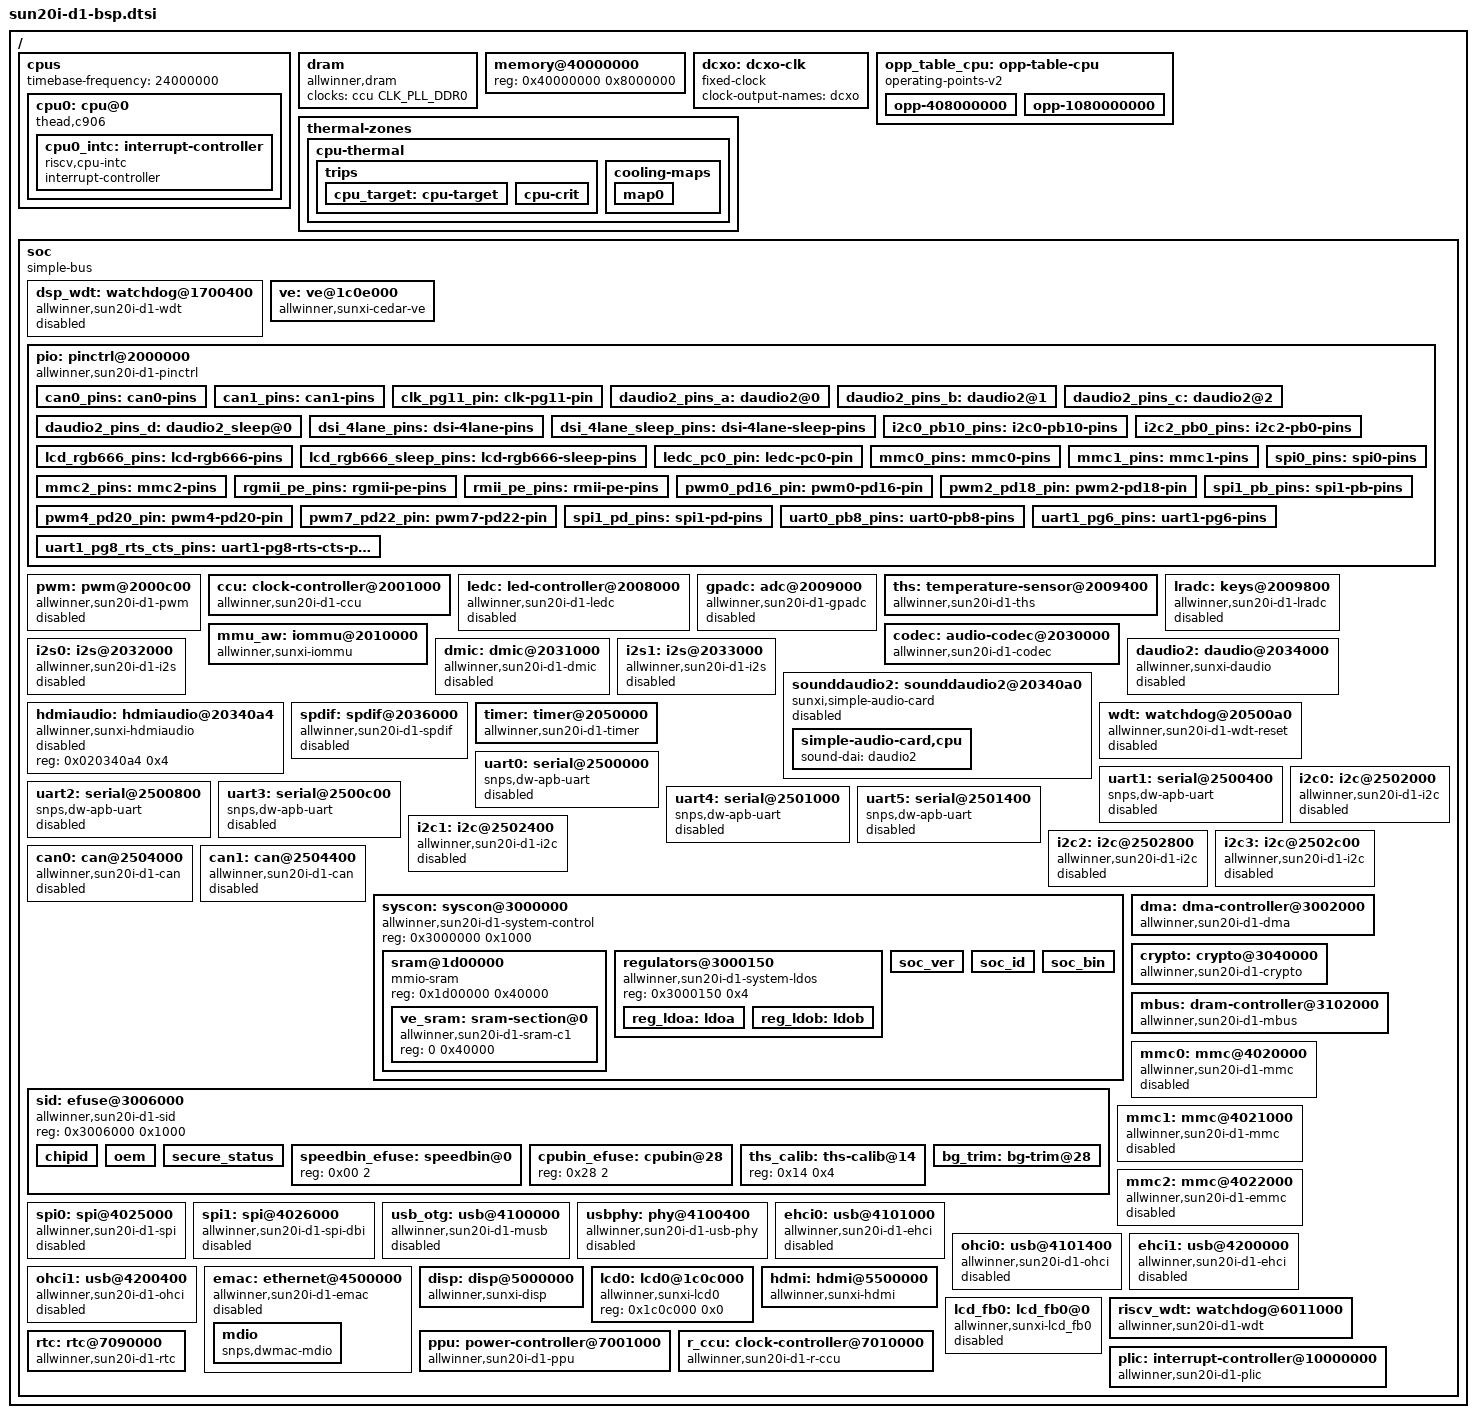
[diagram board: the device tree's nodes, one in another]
// SPDX-License-Identifier: (GPL-2.0+ or MIT)
// Copyright (C) 2021-2022 Samuel Holland <samuel@sholland.org>

/memreserve/ 0x41fc0000 0x020000;  /* opensbi */

#include <dt-bindings/clock/sun6i-rtc.h>
#include <dt-bindings/clock/sun8i-de2.h>
#include <dt-bindings/clock/sun8i-tcon-top.h>
#include <dt-bindings/clock/sun20i-d1-ccu.h>
#include <dt-bindings/clock/sun20i-d1-r-ccu.h>
#include <dt-bindings/gpio/sun4i-gpio.h>
#include <dt-bindings/interrupt-controller/irq.h>
#include <dt-bindings/reset/sun8i-de2.h>
#include <dt-bindings/reset/sun20i-d1-ccu.h>
#include <dt-bindings/reset/sun20i-d1-r-ccu.h>
#include <dt-bindings/thermal/thermal.h>

#define SOC_PERIPHERAL_IRQ(nr)	(nr + 16)

/ {
	#address-cells = <1>;
	#size-cells = <1>;

	cpus {
		timebase-frequency = <24000000>;
		#address-cells = <1>;
		#size-cells = <0>;

		cpu0: cpu@0 {
			compatible = "thead,c906", "riscv";
			device_type = "cpu";
			reg = <0>;
			clocks = <&ccu CLK_RISCV>;
			clock-frequency = <24000000>;
			d-cache-block-size = <64>;
			d-cache-sets = <256>;
			d-cache-size = <32768>;
			i-cache-block-size = <64>;
			i-cache-sets = <128>;
			i-cache-size = <32768>;
			mmu-type = "riscv,sv39";
			operating-points-v2 = <&opp_table_cpu>;
			riscv,isa = "rv64imafdc";
			#cooling-cells = <2>;

			cpu0_intc: interrupt-controller {
				compatible = "riscv,cpu-intc";
				interrupt-controller;
				#address-cells = <0>;
				#interrupt-cells = <1>;
			};
		};
	};

	dram: dram {
		device_type = "dram";
		compatible = "allwinner,dram";
		clocks = <&ccu CLK_PLL_DDR0>;
		clock-names = "pll_ddr";
	};

	memory@40000000 {
		device_type = "memory";
		reg = <0x40000000 0x8000000>;
	};

	dcxo: dcxo-clk {
		compatible = "fixed-clock";
		clock-output-names = "dcxo";
		#clock-cells = <0>;
	};

	opp_table_cpu: opp-table-cpu {
		compatible = "operating-points-v2";

		opp-408000000 {
			opp-hz = /bits/ 64 <408000000>;
			opp-microvolt = <900000 900000 1100000>;
		};

		opp-1080000000 {
			opp-hz = /bits/ 64 <1008000000>;
			opp-microvolt = <900000 900000 1100000>;
		};
	};

	thermal-zones {
		cpu-thermal {
			polling-delay = <0>;
			polling-delay-passive = <0>;
			thermal-sensors = <&ths>;

			trips {
				cpu_target: cpu-target {
					hysteresis = <3000>;
					temperature = <85000>;
					type = "passive";
				};

				cpu-crit {
					hysteresis = <0>;
					temperature = <110000>;
					type = "critical";
				};
			};

			cooling-maps {
				map0 {
					trip = <&cpu_target>;
					cooling-device = <&cpu0 THERMAL_NO_LIMIT THERMAL_NO_LIMIT>;
				};
			};
		};
	};

	soc {
		compatible = "simple-bus";
		ranges;
		interrupt-parent = <&plic>;
		dma-noncoherent;
		#address-cells = <1>;
		#size-cells = <1>;

		dsp_wdt: watchdog@1700400 {
			compatible = "allwinner,sun20i-d1-wdt";
			reg = <0x1700400 0x20>;
			interrupts = <SOC_PERIPHERAL_IRQ(122) IRQ_TYPE_LEVEL_HIGH>;
			clocks = <&dcxo>, <&rtc CLK_OSC32K>;
			clock-names = "hosc", "losc";
			status = "reserved";
		};

		ve: ve@1c0e000 {
			compatible = "allwinner,sunxi-cedar-ve";
			reg = <0x01c0e000 0x1000>,
			      <0x03000000 0x10>,
			      <0x03001000 0x1000>;
			//interrupts-extended = <&plic0 82 IRQ_TYPE_LEVEL_HIGH>;
			interrupts = <SOC_PERIPHERAL_IRQ(66) IRQ_TYPE_LEVEL_HIGH>;
			clocks = <&ccu CLK_BUS_VE>, <&ccu CLK_VE>, <&ccu CLK_MBUS_VE>;
			clock-names = "bus_ve", "ve", "mbus_ve";
			resets = <&ccu RST_BUS_VE>;
			iommus = <&mmu_aw 0 1>;
			//iommus = <&iommu 0>;
			status = "okay";
		};

		pio: pinctrl@2000000 {
			compatible = "allwinner,sun20i-d1-pinctrl";
			reg = <0x2000000 0x800>;
			interrupts = <SOC_PERIPHERAL_IRQ(69) IRQ_TYPE_LEVEL_HIGH>,
				     <SOC_PERIPHERAL_IRQ(71) IRQ_TYPE_LEVEL_HIGH>,
				     <SOC_PERIPHERAL_IRQ(73) IRQ_TYPE_LEVEL_HIGH>,
				     <SOC_PERIPHERAL_IRQ(75) IRQ_TYPE_LEVEL_HIGH>,
				     <SOC_PERIPHERAL_IRQ(77) IRQ_TYPE_LEVEL_HIGH>,
				     <SOC_PERIPHERAL_IRQ(79) IRQ_TYPE_LEVEL_HIGH>;
			clocks = <&ccu CLK_APB0>,
				 <&dcxo>,
				 <&rtc CLK_OSC32K>;
			clock-names = "apb", "hosc", "losc";
			gpio-controller;
			interrupt-controller;
			#gpio-cells = <3>;
			#interrupt-cells = <3>;

			/omit-if-no-ref/
			can0_pins: can0-pins {
				pins = "PB2", "PB3";
				function = "can0";
			};

			/omit-if-no-ref/
			can1_pins: can1-pins {
				pins = "PB4", "PB5";
				function = "can1";
			};

			/omit-if-no-ref/
			clk_pg11_pin: clk-pg11-pin {
				pins = "PG11";
				function = "clk";
			};

			/omit-if-no-ref/
			daudio2_pins_a: daudio2@0 {
				/* I2S_PIN: MCLK, BCLK, LRCK */
				pins = "PB7", "PB5", "PB6";
				function = "i2s2";
				drive-strength = <20>;
				bias-disable;
			};

			/omit-if-no-ref/
			daudio2_pins_b: daudio2@1 {
				/* I2S_PIN: DOUT0 */
				pins = "PB4";
				function = "i2s2_dout";
				drive-strength = <20>;
				bias-disable;
			};

			/omit-if-no-ref/
			daudio2_pins_c: daudio2@2 {
				/* I2S_PIN: DIN0 */
				pins = "PB3";
				function = "i2s2_din";
				drive-strength = <20>;
				bias-disable;
			};

			/omit-if-no-ref/
			daudio2_pins_d: daudio2_sleep@0 {
				pins = "PB7", "PB5", "PB6", "PB4", "PB3";
				function = "io_disabled";
				drive-strength = <20>;
				bias-disable;
			};

			/omit-if-no-ref/
			dsi_4lane_pins: dsi-4lane-pins {
				pins = "PD0", "PD1", "PD2", "PD3", "PD4", "PD5",
				       "PD6", "PD7", "PD8", "PD9";
				drive-strength = <30>;
				function = "dsi";
			};

			/omit-if-no-ref/
			dsi_4lane_sleep_pins: dsi-4lane-sleep-pins {
				pins = "PD0", "PD1", "PD2", "PD3", "PD4", "PD5",
				       "PD6", "PD7", "PD8", "PD9";
				function = "io_disabled";
				bias-disable;
			};

			/omit-if-no-ref/
			i2c0_pb10_pins: i2c0-pb10-pins {
				pins = "PB10", "PB11";
				function = "i2c0";
			};

			/omit-if-no-ref/
			i2c2_pb0_pins: i2c2-pb0-pins {
				pins = "PB0", "PB1";
				function = "i2c2";
			};

			/omit-if-no-ref/
			lcd_rgb666_pins: lcd-rgb666-pins {
				pins = "PD0", "PD1", "PD2", "PD3", "PD4", "PD5",
				       "PD6", "PD7", "PD8", "PD9", "PD10", "PD11",
				       "PD12", "PD13", "PD14", "PD15", "PD16", "PD17",
				       "PD18", "PD19", "PD20", "PD21";
				function = "lcd0";
				drive-strength = <30>;
				bias-disable;
			};

			/omit-if-no-ref/
			lcd_rgb666_sleep_pins: lcd-rgb666-sleep-pins {
				pins = "PD0", "PD1", "PD2", "PD3", "PD4", "PD5", \
					"PD6", "PD7", "PD8", "PD9", "PD10", "PD11", \
					"PD12", "PD13", "PD14", "PD15", "PD16", "PD17", \
					"PD18", "PD19", "PD20", "PD21";
				function = "io_disabled";
				bias-disable;
			};

			/omit-if-no-ref/
			ledc_pc0_pin: ledc-pc0-pin {
				pins = "PC0";
				function = "ledc";
			};

			/omit-if-no-ref/
			mmc0_pins: mmc0-pins {
				pins = "PF0", "PF1", "PF2", "PF3", "PF4", "PF5";
				function = "mmc0";
			};

			/omit-if-no-ref/
			mmc1_pins: mmc1-pins {
				pins = "PG0", "PG1", "PG2", "PG3", "PG4", "PG5";
				function = "mmc1";
			};

			/omit-if-no-ref/
			mmc2_pins: mmc2-pins {
				pins = "PC2", "PC3", "PC4", "PC5", "PC6", "PC7";
				function = "mmc2";
			};

			/omit-if-no-ref/
			rgmii_pe_pins: rgmii-pe-pins {
				pins = "PE0", "PE1", "PE2", "PE3", "PE4",
				       "PE5", "PE6", "PE7", "PE8", "PE9",
				       "PE11", "PE12", "PE13", "PE14", "PE15";
				function = "emac";
			};

			/omit-if-no-ref/
			rmii_pe_pins: rmii-pe-pins {
				pins = "PE0", "PE1", "PE2", "PE3", "PE4",
				       "PE5", "PE6", "PE7", "PE8", "PE9";
				function = "emac";
			};

			/omit-if-no-ref/
			pwm0_pd16_pin: pwm0-pd16-pin {
				pins = "PD16";
				function = "pwm0";
			};

			/omit-if-no-ref/
			pwm2_pd18_pin: pwm2-pd18-pin {
				pins = "PD18";
				function = "pwm2";
			};

			/omit-if-no-ref/
			pwm4_pd20_pin: pwm4-pd20-pin {
				pins = "PD20";
				function = "pwm4";
			};

			/omit-if-no-ref/
			pwm7_pd22_pin: pwm7-pd22-pin {
				pins = "PD22";
				function = "pwm7";
			};

			/omit-if-no-ref/
			spi0_pins: spi0-pins {
				pins = "PC2", "PC3", "PC4", "PC5", "PC6", "PC7";
				function = "spi0";
			};

			/omit-if-no-ref/
			spi1_pb_pins: spi1-pb-pins {
				pins = "PB0", "PB8", "PB9", "PB10", "PB11", "PB12";
				function = "spi1";
			};

			/omit-if-no-ref/
			spi1_pd_pins: spi1-pd-pins {
				pins = "PD10", "PD11", "PD12", "PD13", "PD14", "PD15";
				function = "spi1";
			};

			/omit-if-no-ref/
			uart0_pb8_pins: uart0-pb8-pins {
				pins = "PB8", "PB9";
				function = "uart0";
			};

			/omit-if-no-ref/
			uart1_pg6_pins: uart1-pg6-pins {
				pins = "PG6", "PG7";
				function = "uart1";
			};

			/omit-if-no-ref/
			uart1_pg8_rts_cts_pins: uart1-pg8-rts-cts-pins {
				pins = "PG8", "PG9";
				function = "uart1";
			};
		};

		pwm: pwm@2000c00 {
			compatible = "allwinner,sun20i-d1-pwm";
			reg = <0x2000c00 0x400>;
			interrupts = <SOC_PERIPHERAL_IRQ(18) IRQ_TYPE_LEVEL_HIGH>;
			clocks = <&ccu CLK_BUS_PWM>, <&dcxo>;
			clock-names = "bus", "mod";
			resets = <&ccu RST_BUS_PWM>;
			status = "disabled";
			#pwm-cells = <3>;
		};

		ccu: clock-controller@2001000 {
			compatible = "allwinner,sun20i-d1-ccu";
			reg = <0x2001000 0x1000>;
			clocks = <&dcxo>,
				 <&rtc CLK_OSC32K>,
				 <&rtc CLK_IOSC>;
			clock-names = "hosc", "losc", "iosc";
			#clock-cells = <1>;
			#reset-cells = <1>;
		};

		ledc: led-controller@2008000 {
			compatible = "allwinner,sun20i-d1-ledc",
				     "allwinner,sun50i-a100-ledc";
			reg = <0x2008000 0x400>;
			interrupts = <SOC_PERIPHERAL_IRQ(20) IRQ_TYPE_LEVEL_HIGH>;
			clocks = <&ccu CLK_BUS_LEDC>, <&ccu CLK_LEDC>;
			clock-names = "bus", "mod";
			resets = <&ccu RST_BUS_LEDC>;
			dmas = <&dma 42>;
			dma-names = "tx";
			status = "disabled";
			#address-cells = <1>;
			#size-cells = <0>;
		};

		gpadc: adc@2009000 {
			compatible = "allwinner,sun20i-d1-gpadc";
			reg = <0x2009000 0x400>;
			clocks = <&ccu CLK_BUS_GPADC>;
			resets = <&ccu RST_BUS_GPADC>;
			interrupts = <SOC_PERIPHERAL_IRQ(57) IRQ_TYPE_LEVEL_HIGH>;
			status = "disabled";
			#io-channel-cells = <1>;
		};

		ths: temperature-sensor@2009400 {
			compatible = "allwinner,sun20i-d1-ths";
			reg = <0x2009400 0x400>;
			interrupts = <SOC_PERIPHERAL_IRQ(58) IRQ_TYPE_LEVEL_HIGH>;
			clocks = <&ccu CLK_BUS_THS>, <&dcxo>;
			clock-names = "bus", "mod";
			resets = <&ccu RST_BUS_THS>;
			nvmem-cells = <&ths_calib>;
			nvmem-cell-names = "calibration";
			#thermal-sensor-cells = <0>;
		};

		lradc: keys@2009800 {
			compatible = "allwinner,sun20i-d1-lradc",
				     "allwinner,sun50i-r329-lradc";
			reg = <0x2009800 0x400>;
			interrupts = <SOC_PERIPHERAL_IRQ(61) IRQ_TYPE_LEVEL_HIGH>;
			clocks = <&ccu CLK_BUS_LRADC>;
			resets = <&ccu RST_BUS_LRADC>;
			status = "disabled";
		};

		mmu_aw: iommu@2010000 {
			compatible = "allwinner,sunxi-iommu";
			reg = <0x02010000 0x1000>;
			interrupts = <SOC_PERIPHERAL_IRQ(64) IRQ_TYPE_LEVEL_HIGH>;
			//interrupts-extended = <&plic0 80 IRQ_TYPE_LEVEL_HIGH>;
			interrupt-names = "iommu-irq";
			clocks = <&ccu CLK_BUS_IOMMU>;
			clock-names = "iommu";
			#iommu-cells = <2>;
			status = "okay";
		};

		codec: audio-codec@2030000 {
			compatible = "allwinner,sun20i-d1-codec", "simple-mfd", "syscon";
			reg = <0x2030000 0x1000>;
			interrupts = <SOC_PERIPHERAL_IRQ(25) IRQ_TYPE_LEVEL_HIGH>;
			clocks = <&ccu CLK_BUS_AUDIO>,
				 <&ccu CLK_AUDIO_ADC>,
				 <&ccu CLK_AUDIO_DAC>,
				 <&dcxo>,
				 <&rtc CLK_OSC32K>;
			clock-names = "bus", "adc", "dac", "hosc", "losc";
			resets = <&ccu RST_BUS_AUDIO>;
			dmas = <&dma 7>, <&dma 7>;
			dma-names = "rx", "tx";
			#address-cells = <1>;
			#size-cells = <1>;
			#sound-dai-cells = <0>;
		};

		dmic: dmic@2031000 {
			compatible = "allwinner,sun20i-d1-dmic",
				     "allwinner,sun50i-h6-dmic";
			reg = <0x2031000 0x400>;
			interrupts = <SOC_PERIPHERAL_IRQ(24) IRQ_TYPE_LEVEL_HIGH>;
			clocks = <&ccu CLK_BUS_DMIC>,
				 <&ccu CLK_DMIC>;
			clock-names = "bus", "mod";
			resets = <&ccu RST_BUS_DMIC>;
			dmas = <&dma 8>;
			dma-names = "rx";
			status = "disabled";
			#sound-dai-cells = <0>;
		};

		i2s0: i2s@2032000 {
			compatible = "allwinner,sun20i-d1-i2s",
				     "allwinner,sun50i-r329-i2s";
			reg = <0x2032000 0x1000>;
			interrupts = <SOC_PERIPHERAL_IRQ(26) IRQ_TYPE_LEVEL_HIGH>;
			clocks = <&ccu CLK_BUS_I2S0>,
				 <&ccu CLK_I2S0>;
			clock-names = "apb", "mod";
			resets = <&ccu RST_BUS_I2S0>;
			dmas = <&dma 3>, <&dma 3>;
			dma-names = "rx", "tx";
			status = "disabled";
			#sound-dai-cells = <0>;
		};

		i2s1: i2s@2033000 {
			compatible = "allwinner,sun20i-d1-i2s",
				     "allwinner,sun50i-r329-i2s";
			reg = <0x2033000 0x1000>;
			interrupts = <SOC_PERIPHERAL_IRQ(27) IRQ_TYPE_LEVEL_HIGH>;
			clocks = <&ccu CLK_BUS_I2S1>,
				 <&ccu CLK_I2S1>;
			clock-names = "apb", "mod";
			resets = <&ccu RST_BUS_I2S1>;
			dmas = <&dma 4>, <&dma 4>;
			dma-names = "rx", "tx";
			status = "disabled";
			#sound-dai-cells = <0>;
		};

		/* daudio2 addr: 0x02034000, the others is invalid to avoid build warining */
		daudio2:daudio@2034000 {
			#sound-dai-cells = <0>;
			compatible = "allwinner,sunxi-daudio";
			reg = <0x02034000 0xa0>;
			clocks = <&ccu CLK_PLL_AUDIO0>,
				 <&ccu CLK_I2S2>,
				 <&ccu CLK_BUS_I2S2>,
				 <&ccu CLK_PLL_AUDIO0_4X>,
				 <&ccu CLK_I2S2_ASRC>;
			resets = <&ccu RST_BUS_I2S2>;
			dmas		= <&dma 5>, <&dma 5>;
			dma-names	= "tx", "rx";
			interrupts = <SOC_PERIPHERAL_IRQ(28) IRQ_TYPE_LEVEL_HIGH>;
			//interrupts-extended = <&plic0 44 IRQ_TYPE_LEVEL_HIGH>;
			sign_extend		= <0x00>;
			tx_data_mode		= <0x00>;
			rx_data_mode		= <0x00>;
			msb_lsb_first		= <0x00>;
			pcm_lrck_period		= <0x80>;
			slot_width_select	= <0x20>;
			frametype		= <0x00>;
			tdm_config		= <0x01>;
			tdm_num			= <0x02>;
			mclk_div		= <0x01>;
			clk_parent		= <0x01>;
			capture_cma		= <128>;
			playback_cma		= <128>;
			tx_num			= <4>;
			tx_chmap1		= <0x76543210>;
			tx_chmap0		= <0xFEDCBA98>;
			rx_num			= <4>;
			rx_chmap3		= <0x03020100>;
			rx_chmap2		= <0x07060504>;
			rx_chmap1		= <0x0B0A0908>;
			rx_chmap0		= <0x0F0E0D0C>;
			asrc_function_en	= <0x00>;
			rx_sync_en              = <0x00>;
			device_type = "daudio2";
			status = "disabled";
		};

		sounddaudio2: sounddaudio2@20340a0 {
			reg = <0x020340a0 0x4>;
			compatible = "sunxi,simple-audio-card";
			simple-audio-card,name = "snddaudio2";
			simple-audio-card,format = "i2s";
			status = "disabled";
			simple-audio-card,cpu {
				sound-dai = <&daudio2>;
			};
		};

		hdmiaudio: hdmiaudio@20340a4 {
			#sound-dai-cells = <0>;
			reg = <0x020340a4 0x4>;
			compatible = "allwinner,sunxi-hdmiaudio";
			status = "disabled";
		};

		// TODO: add receive functionality
		spdif: spdif@2036000 {
			compatible = "allwinner,sun20i-d1-spdif";
			reg = <0x2036000 0x400>;
			interrupts = <SOC_PERIPHERAL_IRQ(23) IRQ_TYPE_LEVEL_HIGH>;
			clocks = <&ccu CLK_BUS_SPDIF>,
				 <&ccu CLK_SPDIF_RX>,
				 <&ccu CLK_SPDIF_TX>;
			clock-names = "apb", "rx", "tx";
			resets = <&ccu RST_BUS_SPDIF>;
			dmas = <&dma 2>, <&dma 2>;
			dma-names = "rx", "tx";
			status = "disabled";
			#sound-dai-cells = <0>;
		};

		timer: timer@2050000 {
			compatible = "allwinner,sun20i-d1-timer",
				     "allwinner,sun8i-a23-timer";
			reg = <0x2050000 0xa0>;
			interrupts = <SOC_PERIPHERAL_IRQ(59) IRQ_TYPE_LEVEL_HIGH>,
				     <SOC_PERIPHERAL_IRQ(60) IRQ_TYPE_LEVEL_HIGH>;
			clocks = <&dcxo>;
		};

		wdt: watchdog@20500a0 {
			compatible = "allwinner,sun20i-d1-wdt-reset",
				     "allwinner,sun20i-d1-wdt";
			reg = <0x20500a0 0x20>;
			interrupts = <SOC_PERIPHERAL_IRQ(63) IRQ_TYPE_LEVEL_HIGH>;
			clocks = <&dcxo>, <&rtc CLK_OSC32K>;
			clock-names = "hosc", "losc";
			status = "reserved";
		};

		uart0: serial@2500000 {
			compatible = "snps,dw-apb-uart";
			reg = <0x2500000 0x400>;
			reg-io-width = <4>;
			reg-shift = <2>;
			interrupts = <SOC_PERIPHERAL_IRQ(2) IRQ_TYPE_LEVEL_HIGH>;
			clocks = <&ccu CLK_BUS_UART0>;
			resets = <&ccu RST_BUS_UART0>;
			dmas = <&dma 14>, <&dma 14>;
			dma-names = "rx", "tx";
			status = "disabled";
		};

		uart1: serial@2500400 {
			compatible = "snps,dw-apb-uart";
			reg = <0x2500400 0x400>;
			reg-io-width = <4>;
			reg-shift = <2>;
			interrupts = <SOC_PERIPHERAL_IRQ(3) IRQ_TYPE_LEVEL_HIGH>;
			clocks = <&ccu CLK_BUS_UART1>;
			resets = <&ccu RST_BUS_UART1>;
			dmas = <&dma 15>, <&dma 15>;
			dma-names = "rx", "tx";
			status = "disabled";
		};

		uart2: serial@2500800 {
			compatible = "snps,dw-apb-uart";
			reg = <0x2500800 0x400>;
			reg-io-width = <4>;
			reg-shift = <2>;
			interrupts = <SOC_PERIPHERAL_IRQ(4) IRQ_TYPE_LEVEL_HIGH>;
			clocks = <&ccu CLK_BUS_UART2>;
			resets = <&ccu RST_BUS_UART2>;
			dmas = <&dma 16>, <&dma 16>;
			dma-names = "rx", "tx";
			status = "disabled";
		};

		uart3: serial@2500c00 {
			compatible = "snps,dw-apb-uart";
			reg = <0x2500c00 0x400>;
			reg-io-width = <4>;
			reg-shift = <2>;
			interrupts = <SOC_PERIPHERAL_IRQ(5) IRQ_TYPE_LEVEL_HIGH>;
			clocks = <&ccu CLK_BUS_UART3>;
			resets = <&ccu RST_BUS_UART3>;
			dmas = <&dma 17>, <&dma 17>;
			dma-names = "rx", "tx";
			status = "disabled";
		};

		uart4: serial@2501000 {
			compatible = "snps,dw-apb-uart";
			reg = <0x2501000 0x400>;
			reg-io-width = <4>;
			reg-shift = <2>;
			interrupts = <SOC_PERIPHERAL_IRQ(6) IRQ_TYPE_LEVEL_HIGH>;
			clocks = <&ccu CLK_BUS_UART4>;
			resets = <&ccu RST_BUS_UART4>;
			dmas = <&dma 18>, <&dma 18>;
			dma-names = "rx", "tx";
			status = "disabled";
		};

		uart5: serial@2501400 {
			compatible = "snps,dw-apb-uart";
			reg = <0x2501400 0x400>;
			reg-io-width = <4>;
			reg-shift = <2>;
			interrupts = <SOC_PERIPHERAL_IRQ(7) IRQ_TYPE_LEVEL_HIGH>;
			clocks = <&ccu CLK_BUS_UART5>;
			resets = <&ccu RST_BUS_UART5>;
			dmas = <&dma 19>, <&dma 19>;
			dma-names = "rx", "tx";
			status = "disabled";
		};

		i2c0: i2c@2502000 {
			compatible = "allwinner,sun20i-d1-i2c",
				     "allwinner,sun8i-v536-i2c",
				     "allwinner,sun6i-a31-i2c";
			reg = <0x2502000 0x400>;
			interrupts = <SOC_PERIPHERAL_IRQ(9) IRQ_TYPE_LEVEL_HIGH>;
			clocks = <&ccu CLK_BUS_I2C0>;
			resets = <&ccu RST_BUS_I2C0>;
			dmas = <&dma 43>, <&dma 43>;
			dma-names = "rx", "tx";
			status = "disabled";
			#address-cells = <1>;
			#size-cells = <0>;
		};

		i2c1: i2c@2502400 {
			compatible = "allwinner,sun20i-d1-i2c",
				     "allwinner,sun8i-v536-i2c",
				     "allwinner,sun6i-a31-i2c";
			reg = <0x2502400 0x400>;
			interrupts = <SOC_PERIPHERAL_IRQ(10) IRQ_TYPE_LEVEL_HIGH>;
			clocks = <&ccu CLK_BUS_I2C1>;
			resets = <&ccu RST_BUS_I2C1>;
			dmas = <&dma 44>, <&dma 44>;
			dma-names = "rx", "tx";
			status = "disabled";
			#address-cells = <1>;
			#size-cells = <0>;
		};

		i2c2: i2c@2502800 {
			compatible = "allwinner,sun20i-d1-i2c",
				     "allwinner,sun8i-v536-i2c",
				     "allwinner,sun6i-a31-i2c";
			reg = <0x2502800 0x400>;
			interrupts = <SOC_PERIPHERAL_IRQ(11) IRQ_TYPE_LEVEL_HIGH>;
			clocks = <&ccu CLK_BUS_I2C2>;
			resets = <&ccu RST_BUS_I2C2>;
			dmas = <&dma 45>, <&dma 45>;
			dma-names = "rx", "tx";
			status = "disabled";
			#address-cells = <1>;
			#size-cells = <0>;
		};

		i2c3: i2c@2502c00 {
			compatible = "allwinner,sun20i-d1-i2c",
				     "allwinner,sun8i-v536-i2c",
				     "allwinner,sun6i-a31-i2c";
			reg = <0x2502c00 0x400>;
			interrupts = <SOC_PERIPHERAL_IRQ(12) IRQ_TYPE_LEVEL_HIGH>;
			clocks = <&ccu CLK_BUS_I2C3>;
			resets = <&ccu RST_BUS_I2C3>;
			dmas = <&dma 46>, <&dma 46>;
			dma-names = "rx", "tx";
			status = "disabled";
			#address-cells = <1>;
			#size-cells = <0>;
		};

		can0: can@2504000 {
			compatible = "allwinner,sun20i-d1-can";
			reg = <0x02504000 0x400>;
			interrupts = <SOC_PERIPHERAL_IRQ(21) IRQ_TYPE_LEVEL_HIGH>;
			clocks = <&ccu CLK_BUS_CAN0>;
			resets = <&ccu RST_BUS_CAN0>;
			pinctrl-names = "default";
			pinctrl-0 = <&can0_pins>;
			status = "disabled";
		};

		can1: can@2504400 {
			compatible = "allwinner,sun20i-d1-can";
			reg = <0x02504400 0x400>;
			interrupts = <SOC_PERIPHERAL_IRQ(22) IRQ_TYPE_LEVEL_HIGH>;
			clocks = <&ccu CLK_BUS_CAN1>;
			resets = <&ccu RST_BUS_CAN1>;
			pinctrl-names = "default";
			pinctrl-0 = <&can1_pins>;
			status = "disabled";
		};

		syscon: syscon@3000000 {
			compatible = "allwinner,sun20i-d1-system-control",
				     "allwinner,sunxi-system-control";
			reg = <0x3000000 0x1000>;
			ranges;
			#address-cells = <1>;
			#size-cells = <1>;

			// FIXME: Address is not verified. It is copied from A64/H6.
			sram@1d00000 {
				compatible = "mmio-sram";
				reg = <0x1d00000 0x40000>;
				ranges = <0 0x1d00000 0x40000>;
				#address-cells = <1>;
				#size-cells = <1>;

				ve_sram: sram-section@0 {
					compatible = "allwinner,sun20i-d1-sram-c1",
						     "allwinner,sun4i-a10-sram-c1";
					reg = <0 0x40000>;
				};
			};

			regulators@3000150 {
				compatible = "allwinner,sun20i-d1-system-ldos";
				reg = <0x3000150 0x4>;

				reg_ldoa: ldoa {
				};

				reg_ldob: ldob {
				};
			};

			soc_ver {
				offset = <0x24>;
				mask = <0x7>;
				shift = <0>;
				ver_a = <0x18590000>;
				ver_b = <0x18590002>;
				ver_d = <0x18590003>;
			};

			soc_id {
				offset = <0x200>;
				mask = <0x1>;
				shift = <22>;
			};

			soc_bin {
				offset = <0x0>;
				mask = <0x3ff>;
				shift = <0x0>;
			};
		};

		dma: dma-controller@3002000 {
			compatible = "allwinner,sun20i-d1-dma";
			reg = <0x3002000 0x1000>;
			interrupts = <SOC_PERIPHERAL_IRQ(50) IRQ_TYPE_LEVEL_HIGH>;
			clocks = <&ccu CLK_BUS_DMA>, <&ccu CLK_MBUS_DMA>;
			clock-names = "bus", "mbus";
			resets = <&ccu RST_BUS_DMA>;
			dma-channels = <16>;
			dma-requests = <48>;
			#dma-cells = <1>;
		};

		sid: efuse@3006000 {
			compatible = "allwinner,sun20i-d1-sid",
				     "allwinner,sunxi-sid";
			reg = <0x3006000 0x1000>;
			#address-cells = <1>;
			#size-cells = <1>;

			chipid {
				reg = <0x0 0>;
				offset = <0x200>;
				size = <0x10>;
			};

			oem {
				reg = <0x0 0>;
				offset = <0x238>;
				size = <0x8>;
			};

			secure_status {
				reg = <0x0 0>;
				offset = <0x210>;
				size = <0x4>;
			};

			speedbin_efuse: speedbin@0 {
				reg = <0x00 2>;
			};

			cpubin_efuse: cpubin@28 {
				reg = <0x28 2>;
			};

			ths_calib: ths-calib@14 {
				reg = <0x14 0x4>;
			};

			bg_trim: bg-trim@28 {
				reg = <0x28 0x4>;
				bits = <16 8>;
			};
		};

		crypto: crypto@3040000 {
			compatible = "allwinner,sun20i-d1-crypto",
				     "allwinner,sunxi-ce";
			reg = <0x3040000 0x800>;
			interrupts = <SOC_PERIPHERAL_IRQ(52) IRQ_TYPE_LEVEL_HIGH>;
			clocks = <&ccu CLK_BUS_CE>,
				 <&ccu CLK_CE>,
				 <&ccu CLK_MBUS_CE>,
				 <&rtc CLK_IOSC>;
			clock-names = "bus", "mod", "ram", "trng";
			resets = <&ccu RST_BUS_CE>;
		};

		mbus: dram-controller@3102000 {
			compatible = "allwinner,sun20i-d1-mbus";
			reg = <0x3102000 0x1000>,
			      <0x3103000 0x1000>;
			reg-names = "mbus", "dram";
			interrupts = <SOC_PERIPHERAL_IRQ(43) IRQ_TYPE_LEVEL_HIGH>;
			clocks = <&ccu CLK_MBUS>,
				 <&ccu CLK_DRAM>,
				 <&ccu CLK_BUS_DRAM>;
			clock-names = "mbus", "dram", "bus";
			dma-ranges = <0 0x40000000 0x80000000>;
			#address-cells = <1>;
			#size-cells = <1>;
			#interconnect-cells = <1>;
		};

		mmc0: mmc@4020000 {
			compatible = "allwinner,sun20i-d1-mmc";
			reg = <0x4020000 0x1000>;
			interrupts = <SOC_PERIPHERAL_IRQ(40) IRQ_TYPE_LEVEL_HIGH>;
			clocks = <&ccu CLK_BUS_MMC0>, <&ccu CLK_MMC0>;
			clock-names = "ahb", "mmc";
			resets = <&ccu RST_BUS_MMC0>;
			reset-names = "ahb";
			cap-sd-highspeed;
			max-frequency = <150000000>;
			no-mmc;
			status = "disabled";
			#address-cells = <1>;
			#size-cells = <0>;
		};

		mmc1: mmc@4021000 {
			compatible = "allwinner,sun20i-d1-mmc";
			reg = <0x4021000 0x1000>;
			interrupts = <SOC_PERIPHERAL_IRQ(41) IRQ_TYPE_LEVEL_HIGH>;
			clocks = <&ccu CLK_BUS_MMC1>, <&ccu CLK_MMC1>;
			clock-names = "ahb", "mmc";
			resets = <&ccu RST_BUS_MMC1>;
			reset-names = "ahb";
			cap-sd-highspeed;
			max-frequency = <150000000>;
			no-mmc;
			status = "disabled";
			#address-cells = <1>;
			#size-cells = <0>;
		};

		mmc2: mmc@4022000 {
			compatible = "allwinner,sun20i-d1-emmc",
				     "allwinner,sun50i-a100-emmc";
			reg = <0x4022000 0x1000>;
			interrupts = <SOC_PERIPHERAL_IRQ(42) IRQ_TYPE_LEVEL_HIGH>;
			clocks = <&ccu CLK_BUS_MMC2>, <&ccu CLK_MMC2>;
			clock-names = "ahb", "mmc";
			resets = <&ccu RST_BUS_MMC2>;
			reset-names = "ahb";
			cap-mmc-highspeed;
			max-frequency = <150000000>;
			mmc-ddr-1_8v;
			mmc-ddr-3_3v;
			no-sd;
			no-sdio;
			status = "disabled";
			#address-cells = <1>;
			#size-cells = <0>;
		};

		spi0: spi@4025000 {
			compatible = "allwinner,sun20i-d1-spi",
				     "allwinner,sun50i-r329-spi";
			reg = <0x4025000 0x1000>;
			interrupts = <SOC_PERIPHERAL_IRQ(15) IRQ_TYPE_LEVEL_HIGH>;
			clocks = <&ccu CLK_BUS_SPI0>, <&ccu CLK_SPI0>;
			clock-names = "ahb", "mod";
			resets = <&ccu RST_BUS_SPI0>;
			dmas = <&dma 22>, <&dma 22>;
			dma-names = "rx", "tx";
			num-cs = <1>;
			status = "disabled";
			#address-cells = <1>;
			#size-cells = <0>;
		};

		spi1: spi@4026000 {
			compatible = "allwinner,sun20i-d1-spi-dbi",
				     "allwinner,sun50i-r329-spi-dbi",
				     "allwinner,sun50i-r329-spi";
			reg = <0x4026000 0x1000>;
			interrupts = <SOC_PERIPHERAL_IRQ(16) IRQ_TYPE_LEVEL_HIGH>;
			clocks = <&ccu CLK_BUS_SPI1>, <&ccu CLK_SPI1>;
			clock-names = "ahb", "mod";
			resets = <&ccu RST_BUS_SPI1>;
			dmas = <&dma 23>, <&dma 23>;
			dma-names = "rx", "tx";
			num-cs = <1>;
			status = "disabled";
			#address-cells = <1>;
			#size-cells = <0>;
		};

		usb_otg: usb@4100000 {
			compatible = "allwinner,sun20i-d1-musb",
				     "allwinner,sun8i-a33-musb";
			reg = <0x4100000 0x400>;
			interrupts = <SOC_PERIPHERAL_IRQ(29) IRQ_TYPE_LEVEL_HIGH>;
			interrupt-names = "mc";
			clocks = <&ccu CLK_BUS_OTG>;
			resets = <&ccu RST_BUS_OTG>;
			extcon = <&usbphy 0>;
			phys = <&usbphy 0>;
			phy-names = "usb";
			status = "disabled";
		};

		usbphy: phy@4100400 {
			compatible = "allwinner,sun20i-d1-usb-phy";
			reg = <0x4100400 0x100>,
			      <0x4101800 0x100>,
			      <0x4200800 0x100>;
			reg-names = "phy_ctrl",
				    "pmu0",
				    "pmu1";
			clocks = <&dcxo>,
				 <&dcxo>;
			clock-names = "usb0_phy",
				      "usb1_phy";
			resets = <&ccu RST_USB_PHY0>,
				 <&ccu RST_USB_PHY1>;
			reset-names = "usb0_reset",
				      "usb1_reset";
			status = "disabled";
			#phy-cells = <1>;
		};

		ehci0: usb@4101000 {
			compatible = "allwinner,sun20i-d1-ehci",
				     "generic-ehci";
			reg = <0x4101000 0x100>;
			interrupts = <SOC_PERIPHERAL_IRQ(30) IRQ_TYPE_LEVEL_HIGH>;
			clocks = <&ccu CLK_BUS_OHCI0>,
				 <&ccu CLK_BUS_EHCI0>,
				 <&ccu CLK_USB_OHCI0>;
			resets = <&ccu RST_BUS_OHCI0>,
				 <&ccu RST_BUS_EHCI0>;
			phys = <&usbphy 0>;
			phy-names = "usb";
			status = "disabled";
		};

		ohci0: usb@4101400 {
			compatible = "allwinner,sun20i-d1-ohci",
				     "generic-ohci";
			reg = <0x4101400 0x100>;
			interrupts = <SOC_PERIPHERAL_IRQ(31) IRQ_TYPE_LEVEL_HIGH>;
			clocks = <&ccu CLK_BUS_OHCI0>,
				 <&ccu CLK_USB_OHCI0>;
			resets = <&ccu RST_BUS_OHCI0>;
			phys = <&usbphy 0>;
			phy-names = "usb";
			status = "disabled";
		};

		ehci1: usb@4200000 {
			compatible = "allwinner,sun20i-d1-ehci",
				     "generic-ehci";
			reg = <0x4200000 0x100>;
			interrupts = <SOC_PERIPHERAL_IRQ(33) IRQ_TYPE_LEVEL_HIGH>;
			clocks = <&ccu CLK_BUS_OHCI1>,
				 <&ccu CLK_BUS_EHCI1>,
				 <&ccu CLK_USB_OHCI1>;
			resets = <&ccu RST_BUS_OHCI1>,
				 <&ccu RST_BUS_EHCI1>;
			phys = <&usbphy 1>;
			phy-names = "usb";
			status = "disabled";
		};

		ohci1: usb@4200400 {
			compatible = "allwinner,sun20i-d1-ohci",
				     "generic-ohci";
			reg = <0x4200400 0x100>;
			interrupts = <SOC_PERIPHERAL_IRQ(34) IRQ_TYPE_LEVEL_HIGH>;
			clocks = <&ccu CLK_BUS_OHCI1>,
				 <&ccu CLK_USB_OHCI1>;
			resets = <&ccu RST_BUS_OHCI1>;
			phys = <&usbphy 1>;
			phy-names = "usb";
			status = "disabled";
		};

		emac: ethernet@4500000 {
			compatible = "allwinner,sun20i-d1-emac",
				     "allwinner,sun50i-a64-emac";
			reg = <0x4500000 0x10000>;
			interrupts = <SOC_PERIPHERAL_IRQ(46) IRQ_TYPE_LEVEL_HIGH>;
			interrupt-names = "macirq";
			clocks = <&ccu CLK_BUS_EMAC>;
			clock-names = "stmmaceth";
			resets = <&ccu RST_BUS_EMAC>;
			reset-names = "stmmaceth";
			syscon = <&syscon>;
			status = "disabled";

			mdio: mdio {
				compatible = "snps,dwmac-mdio";
				#address-cells = <1>;
				#size-cells = <0>;
			};
		};

		disp: disp@5000000 {
			compatible = "allwinner,sunxi-disp";
			reg = <0x05000000 0x3fffff>,	/* de0 */
			      <0x05460000 0xfff>,	/*display_if_top*/
			      <0x05461000 0xfff>,	/* tcon-lcd0 */
			      <0x05470000 0xfff>,	/* tcon-tv */
			      <0x05450000 0x1fff>;	/* dsi0*/
/*			interrupts = <GIC_SPI 90 IRQ_TYPE_LEVEL_HIGH>,tcon-lcd0
				     <GIC_SPI 91 IRQ_TYPE_LEVEL_HIGH>,tcon-tv
				     <GIC_SPI 92 IRQ_TYPE_LEVEL_HIGH>;dsi*/
			interrupts = <SOC_PERIPHERAL_IRQ(90) IRQ_TYPE_LEVEL_HIGH>,
				     <SOC_PERIPHERAL_IRQ(91) IRQ_TYPE_LEVEL_HIGH>,
				     <SOC_PERIPHERAL_IRQ(92) IRQ_TYPE_LEVEL_HIGH>;
/*			interrupts-extended = <&plic0 106 IRQ_TYPE_LEVEL_HIGH>,
					      <&plic0 107 IRQ_TYPE_LEVEL_HIGH>,
					      <&plic0 108 IRQ_TYPE_LEVEL_HIGH>;*/

			clocks = <&ccu CLK_DE>,
				 <&ccu CLK_DE>,
				 <&ccu CLK_BUS_DE>,
				 <&ccu CLK_BUS_DE>,
				 <&ccu CLK_BUS_DPSS_TOP>,
				 <&ccu CLK_BUS_DPSS_TOP>,
				 <&ccu CLK_MIPI_DSI>,
				 <&ccu CLK_BUS_MIPI_DSI>,
				 <&ccu CLK_TCON_LCD0>,
				 <&ccu CLK_TCON_TV>,
				 <&ccu CLK_BUS_TCON_LCD0>,
				 <&ccu CLK_BUS_TCON_TV>,
				 <&ccu CLK_MIPI_DSI>,
				 <&ccu CLK_BUS_MIPI_DSI>;
			clock-names = "clk_de0",
					"clk_de1",
					"clk_bus_de0",
					"clk_bus_de1",
					"clk_bus_dpss_top0",
					"clk_bus_dpss_top1",
					"clk_mipi_dsi0",
					"clk_bus_mipi_dsi0",
					"clk_tcon0",
					"clk_tcon1",/*tcon-tv actually*/
					"clk_bus_tcon0",
					"clk_bus_tcon1",/*tcon-tv actually*/
					"clk_mipi_dsi0",
					"clk_bus_mipi_dsi0";
			resets = <&ccu RST_BUS_DE>,
				 <&ccu RST_BUS_DE>,
				 <&ccu RST_BUS_DPSS_TOP>,
				 <&ccu RST_BUS_DPSS_TOP>,
				 <&ccu RST_BUS_MIPI_DSI>,
				 <&ccu RST_BUS_TCON_LCD0>,
				 <&ccu RST_BUS_TCON_TV>,
				 <&ccu RST_BUS_LVDS0>;
			reset-names = "rst_bus_de0",
					"rst_bus_de1",
					"rst_bus_dpss_top0",
					"rst_bus_dpss_top1",
					"rst_bus_mipi_dsi0",
					"rst_bus_tcon0",
					"rst_bus_tcon1",
					"rst_bus_lvds0";

			assigned-clocks = <&ccu CLK_DE>,
			<&ccu CLK_MIPI_DSI>,
			<&ccu CLK_TCON_LCD0>,
			<&ccu CLK_TCON_TV>;
			assigned-clock-parents = <&ccu CLK_PLL_PERIPH0_2X>,
			<&ccu CLK_PLL_PERIPH0>,
			<&ccu CLK_PLL_VIDEO0_4X>,
			<&ccu CLK_PLL_VIDEO1_4X>;
			assigned-clock-rates = <300000000>,
			<150000000>,
			<0>,
			<0>;

			boot_disp = <0>;
			boot_disp1 = <0>;
			boot_disp2 = <0>;
			fb_base = <0>;
			iommus = <&mmu_aw 2 0>;
			//iommus = <&iommu 2>;
			status = "okay";
		};

		lcd0: lcd0@1c0c000 {
			compatible = "allwinner,sunxi-lcd0";
			reg = <0x1c0c000 0x0>;  /* Fake registers to avoid dtc compiling warnings */
			pinctrl-names = "active","sleep";
			status = "okay";
		};

		hdmi: hdmi@5500000 {
			compatible = "allwinner,sunxi-hdmi";
			reg = <0x05500000 0xfffff>;
			interrupts = <SOC_PERIPHERAL_IRQ(77) IRQ_TYPE_LEVEL_HIGH>;
			//interrupts = <SOC_PERIPHERAL_IRQ(93) IRQ_TYPE_LEVEL_HIGH>;
			//interrupts-extended = <&plic0 93 IRQ_TYPE_LEVEL_HIGH>;
			clocks = <&ccu CLK_BUS_HDMI>,
				<&ccu CLK_HDMI_24M>,
				<&ccu CLK_HDMI_CEC>,
				<&ccu CLK_TCON_TV>;
			clock-names = "clk_bus_hdmi",
					"clk_ddc",
					"clk_cec",
					"clk_tcon_tv";
			resets = <&ccu RST_BUS_HDMI_SUB>,
				<&ccu RST_BUS_HDMI_MAIN>;
			reset-names = "rst_bus_sub",
				      "rst_bus_main";
			assigned-clocks = <&ccu CLK_HDMI_CEC>;
			assigned-clock-parents = <&ccu CLK_HDMI_CEC_32K>;
			assigned-clock-rates = <0>;
			status = "okay";
		};

		lcd_fb0: lcd_fb0@0 {
			compatible = "allwinner,sunxi-lcd_fb0";
			pinctrl-names = "active","sleep";
			status = "disabled";
		};

		riscv_wdt: watchdog@6011000 {
			compatible = "allwinner,sun20i-d1-wdt";
			reg = <0x6011000 0x20>;
			interrupts = <SOC_PERIPHERAL_IRQ(131) IRQ_TYPE_LEVEL_HIGH>;
			clocks = <&dcxo>, <&rtc CLK_OSC32K>;
			clock-names = "hosc", "losc";
		};

		ppu: power-controller@7001000 {
			compatible = "allwinner,sun20i-d1-ppu";
			reg = <0x7001000 0x1000>;
			clocks = <&r_ccu CLK_BUS_R_PPU>;
			resets = <&r_ccu RST_BUS_R_PPU>;
			#power-domain-cells = <1>;
		};

		r_ccu: clock-controller@7010000 {
			compatible = "allwinner,sun20i-d1-r-ccu";
			reg = <0x7010000 0x400>;
			clocks = <&dcxo>,
				 <&rtc CLK_OSC32K>,
				 <&rtc CLK_IOSC>,
				 <&ccu CLK_PLL_PERIPH0_DIV3>;
			clock-names = "hosc", "losc", "iosc", "pll-periph";
			#clock-cells = <1>;
			#reset-cells = <1>;
		};

		rtc: rtc@7090000 {
			compatible = "allwinner,sun20i-d1-rtc",
				     "allwinner,sun50i-r329-rtc";
			reg = <0x7090000 0x400>;
			interrupts = <SOC_PERIPHERAL_IRQ(144) IRQ_TYPE_LEVEL_HIGH>;
			clocks = <&r_ccu CLK_BUS_R_RTC>,
				 <&dcxo>,
				 <&r_ccu CLK_R_AHB>;
			clock-names = "bus", "hosc", "ahb";
			#clock-cells = <1>;
		};

		plic: interrupt-controller@10000000 {
			compatible = "allwinner,sun20i-d1-plic",
				     "thead,c900-plic";
			reg = <0x10000000 0x4000000>;
			interrupts-extended = <&cpu0_intc 11>,
					      <&cpu0_intc 9>;
			interrupt-controller;
			riscv,ndev = <176>;
			#address-cells = <0>;
			#interrupt-cells = <2>;
		};
	};
};
